# STM32WL5x_CM0P register map
File version: 1.5
CPU: CM0 r0p1, little endian, MPU, no FPU, 4 interrupt priority bits
Registers are 32-bit, read-write, reset 0x0 unless marked. A register's access mark holds for its fields unless they carry their own. Offsets are from the block's base; [hi:lo] are bit positions; {n}, {i} and the like mark numbered series.

## TIM1 — Advanced-control timers
Base 0x40012C00
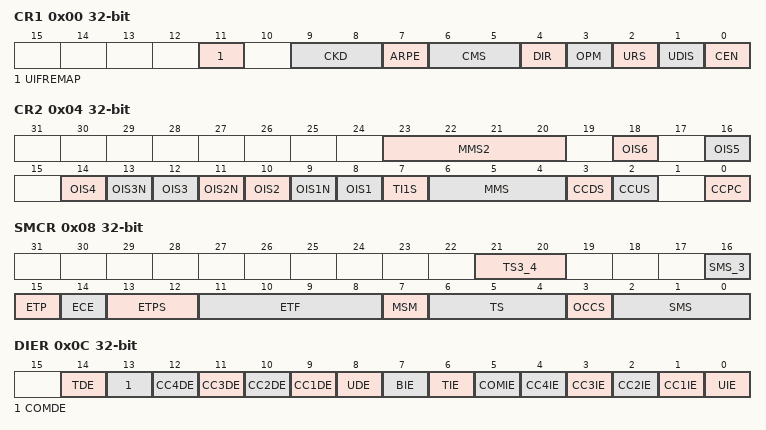
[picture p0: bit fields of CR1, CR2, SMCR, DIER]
0x00 CR1 — control register 1
  [11] UIFREMAP — UIF status bit remapping
  [9:8] CKD — Clock division
  [7] ARPE — Auto-reload preload enable
  [6:5] CMS — Center-aligned mode selection
  [4] DIR — Direction
  [3] OPM — One pulse mode
  [2] URS — Update request source
  [1] UDIS — Update disable
  [0] CEN — Counter enable
0x04 CR2 — control register 2
  [23:20] MMS2 — Master mode selection 2
  [2n+6] OIS{n} (n=1..6) — Output Idle state {n} (OC{n} output)
  [13] OIS3N — Output Idle state 3 (OC3N output)
  [11] OIS2N — Output Idle state 2 (OC2N output)
  [9] OIS1N — Output Idle state 1 (OC1N output)
  [7] TI1S — TI1 selection
  [6:4] MMS — Master mode selection
  [3] CCDS — Capture/compare DMA selection
  [2] CCUS — Capture/compare control update selection
  [0] CCPC — Capture/compare preloaded control
0x08 SMCR — slave mode control register
  [21:20] TS3_4 — Trigger selection
  [16] SMS_3 — Slave mode selection
  [15] ETP — External trigger polarity
  [14] ECE — External clock enable
  [13:12] ETPS — External trigger prescaler
  [11:8] ETF — External trigger filter
  [7] MSM — Master/slave mode
  [6:4] TS — Trigger selection
  [3] OCCS — OCREF clear selection
  [2:0] SMS — Slave mode selection
0x0C DIER — DMA/interrupt enable register
  [14] TDE — Trigger DMA request enable
  [13] COMDE — COM DMA request enable
  [n+8] CC{n}DE (n=1..4) — Capture/Compare {n} DMA request enable
  [8] UDE — Update DMA request enable
  [7] BIE — Break interrupt enable
  [6] TIE — Trigger interrupt enable
  [5] COMIE — COM interrupt enable
  [n] CC{n}IE (n=1..4) — Capture/Compare {n} interrupt enable
  [0] UIE — Update interrupt enable
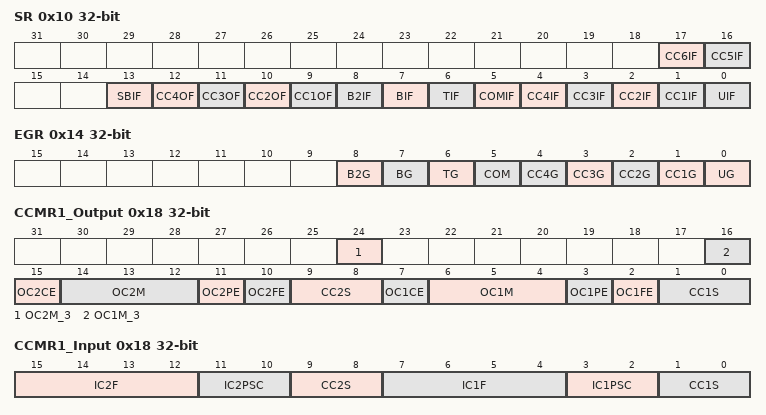
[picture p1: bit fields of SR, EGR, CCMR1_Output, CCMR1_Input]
0x10 SR — status register
  [17] CC6IF — Compare 6 interrupt flag
  [16] CC5IF — Compare 5 interrupt flag
  [13] SBIF — System Break interrupt flag
  [n+8] CC{n}OF (n=1..4) — Capture/Compare {n} overcapture flag
  [8] B2IF — Break 2 interrupt flag
  [7] BIF — Break interrupt flag
  [6] TIF — Trigger interrupt flag
  [5] COMIF — COM interrupt flag
  [n] CC{n}IF (n=1..4) — Capture/Compare {n} interrupt flag
  [0] UIF — Update interrupt flag
0x14 EGR wo — event generation register
  [8] B2G — Break 2 generation
  [7] BG — Break generation
  [6] TG — Trigger generation
  [5] COM — Capture/Compare control update generation
  [n] CC{n}G (n=1..4) — Capture/Compare {n} generation
  [0] UG — Update generation
0x18 CCMR1_Output — capture/compare mode register 1 (output mode)
  [24] OC2M_3 — Output Compare 2 mode - bit 3
  [16] OC1M_3 — Output Compare 1 mode - bit 3
  [15] OC2CE — Output compare 2 clear enable
  [14:12] OC2M — Output compare 2 mode
  [11] OC2PE — Output compare 2 preload enable
  [10] OC2FE — Output compare 2 fast enable
  [9:8] CC2S — Capture/Compare 2 selection
  [7] OC1CE — Output compare 1 clear enable
  [6:4] OC1M — Output compare 1 mode
  [3] OC1PE — Output compare 1 preload enable
  [2] OC1FE — Output compare 1 fast enable
  [1:0] CC1S — Capture/Compare 1 selection
0x18 CCMR1_Input (alternate view of CCMR1_Output) — capture/compare mode register 1 (input mode)
  [15:12] IC2F — Input capture 2 filter
  [11:10] IC2PSC — Input capture 2 prescaler
  [9:8] CC2S — Capture/compare 2 selection
  [7:4] IC1F — Input capture 1 filter
  [3:2] IC1PSC — Input capture 1 prescaler
  [1:0] CC1S — Capture/Compare 1 selection
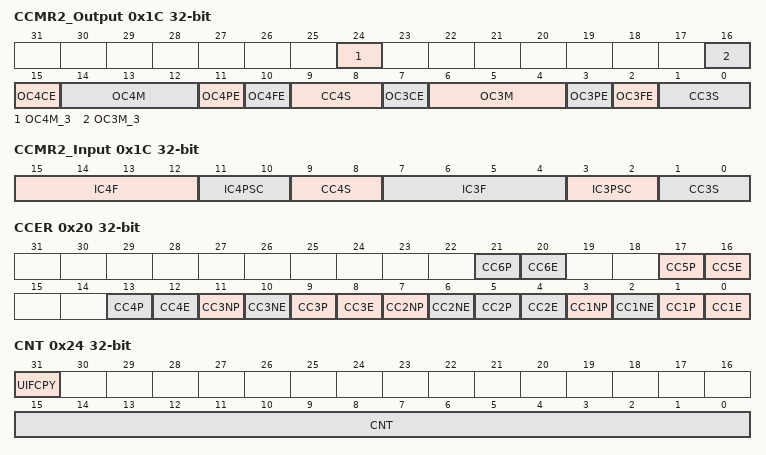
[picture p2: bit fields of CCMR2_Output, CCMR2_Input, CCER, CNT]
0x1C CCMR2_Output — capture/compare mode register 2 (output mode)
  [24] OC4M_3 — Output Compare 4 mode - bit 3
  [16] OC3M_3 — Output Compare 3 mode - bit 3
  [15] OC4CE — Output compare 4 clear enable
  [14:12] OC4M — Output compare 4 mode
  [11] OC4PE — Output compare 4 preload enable
  [10] OC4FE — Output compare 4 fast enable
  [9:8] CC4S — Capture/Compare 4 selection
  [7] OC3CE — Output compare 3 clear enable
  [6:4] OC3M — Output compare 3 mode
  [3] OC3PE — Output compare 3 preload enable
  [2] OC3FE — Output compare 3 fast enable
  [1:0] CC3S — Capture/Compare 3 selection
0x1C CCMR2_Input (alternate view of CCMR2_Output) — capture/compare mode register 2 (input mode)
  [15:12] IC4F — Input capture 4 filter
  [11:10] IC4PSC — Input capture 4 prescaler
  [9:8] CC4S — Capture/Compare 4 selection
  [7:4] IC3F — Input capture 3 filter
  [3:2] IC3PSC — Input capture 3 prescaler
  [1:0] CC3S — Capture/Compare 3 selection
0x20 CCER — capture/compare enable register
  [4n-3] CC{n}P (n=1..6), [4n-4] CC{n}E (n=1..6), [11] CC3NP, [10] CC3NE, [7] CC2NP, [6] CC2NE, [3] CC1NP, [2] CC1NE
0x24 CNT access per field — counter
  [31] UIFCPY ro — UIF copy
  [15:0] CNT rw
0x28 PSC — prescaler
  [15:0] PSC — Prescaler value
0x2C ARR reset 0xFFFF — auto-reload register
  [15:0] ARR — Auto-reload value
0x30 RCR — repetition counter register
  [15:0] REP — Repetition counter value
0x34 CCR1 — capture/compare register 1
  [15:0] CCR1 — Capture/Compare 1 value
0x38 CCR2 — capture/compare register 2
  [15:0] CCR2 — Capture/Compare 2 value
0x3C CCR3 — capture/compare register 3
  [15:0] CCR3 — Capture/Compare value
0x40 CCR4 — capture/compare register 4
  [15:0] CCR4 — Capture/Compare value
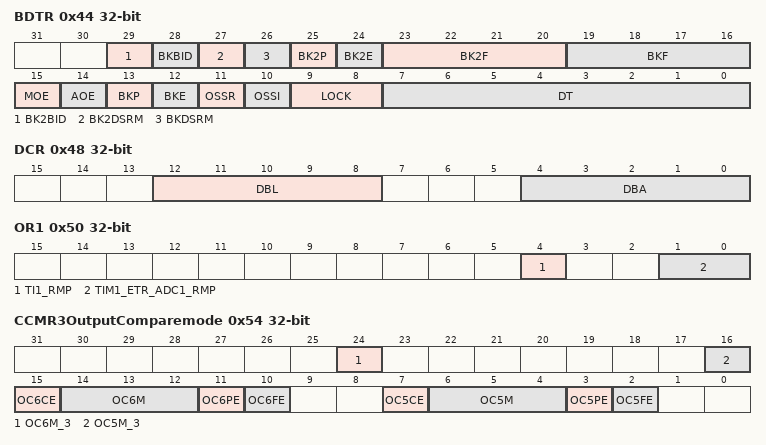
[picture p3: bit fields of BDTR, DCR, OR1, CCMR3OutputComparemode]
0x44 BDTR — break and dead-time register
  [29] BK2BID — Break2 bidirectional
  [28] BKBID
  [27] BK2DSRM — Break2 Disarm
  [26] BKDSRM
  [25] BK2P — Break 2 polarity
  [24] BK2E — Break 2 enable
  [23:20] BK2F — Break 2 filter
  [19:16] BKF — Break filter
  [15] MOE — Main output enable
  [14] AOE — Automatic output enable
  [13] BKP — Break polarity
  [12] BKE — Break enable
  [11] OSSR — Off-state selection for Run mode
  [10] OSSI — Off-state selection for Idle mode
  [9:8] LOCK — Lock configuration
  [7:0] DT — Dead-time generator setup
0x48 DCR — DMA control register
  [12:8] DBL — DMA burst length
  [4:0] DBA — DMA base address
0x4C DMAR — DMA address for full transfer
  [15:0] DMAB — DMA register for burst accesses
0x50 OR1 — option register 1
  [4] TI1_RMP — Input Capture 1 remap
  [1:0] TIM1_ETR_ADC1_RMP — TIM1_ETR_ADC1 remapping capability
0x54 CCMR3OutputComparemode — capture/compare mode register 3
  [24] OC6M_3 — OC6M
  [16] OC5M_3 — OC5M
  [15] OC6CE
  [14:12] OC6M
  [11] OC6PE
  [10] OC6FE
  [7] OC5CE
  [6:4] OC5M
  [3] OC5PE
  [2] OC5FE
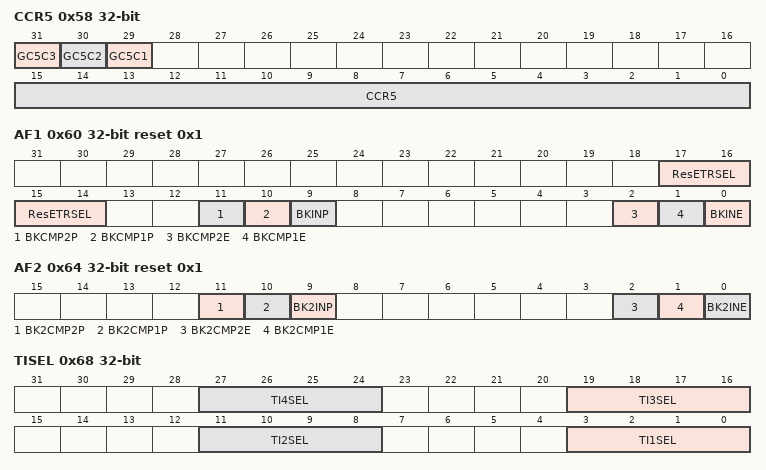
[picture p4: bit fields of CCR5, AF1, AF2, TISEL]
0x58 CCR5 — capture/compare register 5
  [31] GC5C3 — Group Channel 5 and Channel 3
  [30] GC5C2 — Group Channel 5 and Channel 2
  [29] GC5C1 — Group Channel 5 and Channel 1
  [15:0] CCR5 — Capture/Compare 5 value
0x5C CCR6 — capture/compare register 6
  [15:0] CCR6 — Capture/Compare 6 value
0x60 AF1 reset 0x1 — alternate function option register 1
  [17:14] ResETRSEL — ETR source selection
  [11] BKCMP2P — BRK COMP2 input polarity
  [10] BKCMP1P — BRK COMP1 input polarity
  [9] BKINP — BRK BKIN input polarity
  [2] BKCMP2E — BRK COMP2 enable
  [1] BKCMP1E — BRK COMP1 enable
  [0] BKINE — BRK BKIN input enable
0x64 AF2 reset 0x1 — Alternate function register 2
  [11] BK2CMP2P — BRK2 COMP2 input polarity
  [10] BK2CMP1P — BRK2 COMP1 input polarity
  [9] BK2INP — BRK2 BKIN2 input polarity
  [2] BK2CMP2E — BRK2 COMP2 enable
  [1] BK2CMP1E — BRK2 COMP1 enable
  [0] BK2INE — BRK2 BKIN input enable
0x68 TISEL — timer input selection register
  [8n-5:8n-8] TI{n}SEL (n=1..4) — selects TI{n}[0] to TI{n}[15] input
